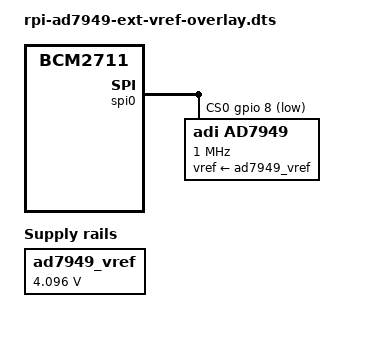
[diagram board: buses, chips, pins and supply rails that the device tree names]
// SPDX-License-Identifier: GPL-2.0

/dts-v1/;
/plugin/;

#include <dt-bindings/gpio/gpio.h>

/ {
	compatible = "brcm,bcm2835", "brcm,bcm2711";
};

&{/} {
	ad7949_vref: fixed-regulator@1 {
		compatible = "regulator-fixed";
		regulator-name = "fixed-supply";
		regulator-min-microvolt = <4096000>;
		regulator-max-microvolt = <4096000>;
		regulator-boot-on;
	};
};

&spi0 {
	status = "okay";

	cs-gpios = <&gpio 8 GPIO_ACTIVE_LOW>;

	ad7949@0 {
		compatible = "adi,ad7949";
		reg = <0x0>;
		spi-max-frequency = <1000000>;
		vref-supply = <&ad7949_vref>;
	};
};

&spidev0 {
	status = "disabled";
};

&spidev1 {
	status = "disabled";
};
